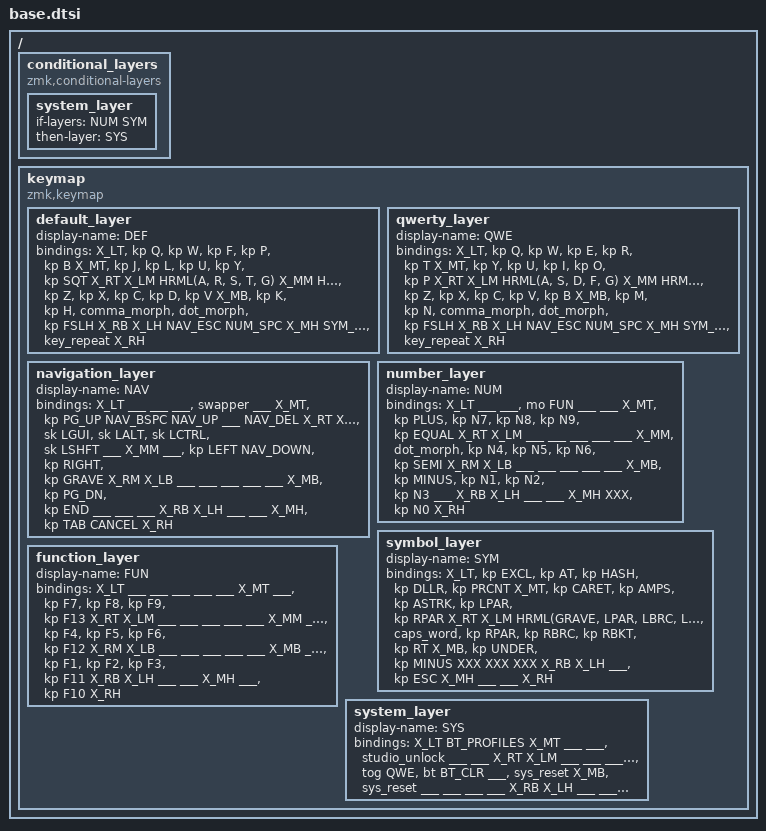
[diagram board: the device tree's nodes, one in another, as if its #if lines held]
// vim: set ts=4 sw=4 ft=devicetree foldmethod=marker foldmarker=[[[,]]]:

#include <behaviors.dtsi>
#include <dt-bindings/zmk/keys.h>
#include <dt-bindings/zmk/bt.h>

//[[[
/////////////////////////////////////////
// Layers
/////////////////////////////////////////
// Layers: Default, Qwerty, Navigation, Number, Symbol, System
#define DEF 0
#define QWE 1
#define NAV 2
#define NUM 3
#define SYM 4
#define FUN 5
#define SYS 6
/////////////////////////////////////////
//]]]



//[[[
/////////////////////////////////////////
// Variables
/////////////////////////////////////////
#define XXX &none
#define ___ &trans
#define KEYS_L LT0 LT1 LT2 LT3 LT4 LM0 LM1 LM2 LM3 LM4 LB0 LB1 LB2 LB3 LB4 // left hand
#define KEYS_R RT0 RT1 RT2 RT3 RT4 RM0 RM1 RM2 RM3 RM4 RB0 RB1 RB2 RB3 RB4 // right hand

#if defined LH2
  #define THUMBS LH2 LH1 LH0 RH0 RH1 RH2 // thumbs on 36 keys
#else
  #define THUMBS LH1 LH0 RH0 RH1 // thumbs on 34 keys
#endif

#ifdef CONFIG_WIRELESS
    #define BT_PROFILES &bt BT_SEL 0 &bt BT_SEL 1 &bt BT_SEL 2 &bt BT_SEL 3 &bt BT_SEL 4
#else
    #define BT_PROFILES ___ ___ ___ ___ ___
#endif
/////////////////////////////////////////
//]]]



//[[[
/////////////////////////////////////////
// Import functionalities
/////////////////////////////////////////
#include "fillers.dtsi"
#include "morph.dtsi"
#include "combos.dtsi"
#include "behaviors.dtsi"
/////////////////////////////////////////
//]]]



//[[[
/////////////////////////////////////////
// Aliases
/////////////////////////////////////////
//      Hyper       keys
#define LEFT_HYPER  LS(LC(LA(LGUI)))
#define LHYPER      LEFT_HYPER
#define LMEH        LS(LC(LALT))
#define RIGHT_HYPER RS(RC(RA(RGUI)))
#define RHYPER      RIGHT_HYPER
#define RMEH        RS(RC(RALT))
//      aliases
#define BTLOADER    &bootloader
#define CANCEL      &kp K_CANCEL
#define NAV_BSPC    &mt LC(BSPC) BSPC
#define NAV_DEL     &mt LC(DEL)  DEL
#define NAV_DOWN    &mt LC(END)  DOWN
#define NAV_UP      &mt LC(HOME) UP
#define STUDIO      &studio_unlock

//      layer       aliases
#define NAV_ESC     &escape_morph
#define NUM_SPC     &space_morph
#define SYM_ENT     &lt SYM ENTER

//      some        functions
#define LH(key)     LS(LC(LA(LG(key))))
#define LM(key)     LS(LC(LA(key)))
#define RH(key)     RS(RC(RA(RG(key))))
#define RM(key)     RS(RC(RA(key)))
/////////////////////////////////////////
//]]]



//[[[
/////////////////////////////////////////
// Home row mods macro
/////////////////////////////////////////
// GUI -> ALT -> CTRL -> SHFT  -> HYPER    |    HYPER -> SHFT -> CTRL -> ALT -> GUI
#define HRML(k1,k2,k3,k4,k5) &hml LGUI  k1 &hml LALT  k2 &hml LCTRL k3 &hml LSHFT k4 &hml LHYPER k5
#define HRMR(k1,k2,k3,k4,k5) &hmr RHYPER k1 &hmr RSHFT k2 &hmr RCTRL k3 &hmr RALT  k4 &hmr RGUI  k5
/////////////////////////////////////////
//]]]



//[[[
/////////////////////////////////////////
// Keymap config
/////////////////////////////////////////
/ {
    conditional_layers {
        compatible = "zmk,conditional-layers";
        system_layer {
            if-layers = <NUM SYM>;
            then-layer = <SYS>;
        };
    };

    keymap {
        compatible = "zmk,keymap";
        default_layer {
            display-name = "DEF";
            bindings = <
        //╭──────╮ ╭──────────┬──────────┬──────────┬──────────┬──────────╮ ╭──────╮ ╭──────────┬──────────┬──────────┬──────────┬──────────╮ ╭──────╮
            X_LT     &kp Q      &kp W      &kp F      &kp P      &kp B        X_MT     &kp J      &kp L      &kp U      &kp Y      &kp SQT      X_RT
        //├──────┤ ├──────────┼──────────┼──────────┼──────────┼──────────┤ ├──────┤ ├──────────┼──────────┼──────────┼──────────┼──────────┤ ├──────┤
            X_LM     HRML(A,        R,         S,         T,        G)        X_MM     HRMR(M,       N,        E,         I,          O)        X_RM
        //├──────┤ ├──────────┼──────────┼──────────┼──────────┼──────────┤ ├──────┤ ├──────────┼──────────┼──────────┼──────────┼──────────┤ ├──────┤
            X_LB     &kp Z      &kp X      &kp C      &kp D      &kp V        X_MB     &kp K      &kp H      &comma_morph  &dot_morph &kp FSLH  X_RB
        //├──────┤ ╰──────────┴──────────┴──────────┼──────────┼──────────┤ ├──────┤ ├──────────┼──────────┼──────────┴──────────┴──────────╯ ├──────┤
            X_LH                                      NAV_ESC    NUM_SPC      X_MH     SYM_ENT    &key_repeat                                   X_RH
        //╰──────╯                                  ╰──────────┴──────────╯ ╰──────╯ ╰──────────┴──────────╯                                  ╰──────╯
            >;
        };

        qwerty_layer {
            display-name = "QWE";
            bindings = <
        //╭──────╮ ╭──────────┬──────────┬──────────┬──────────┬──────────╮ ╭──────╮ ╭──────────┬──────────┬──────────┬──────────┬──────────╮ ╭──────╮
            X_LT     &kp Q      &kp W      &kp E      &kp R      &kp T        X_MT     &kp Y      &kp U      &kp I      &kp O      &kp P        X_RT
        //├──────┤ ├──────────┼──────────┼──────────┼──────────┼──────────┤ ├──────┤ ├──────────┼──────────┼──────────┼──────────┼──────────┤ ├──────┤
            X_LM     HRML(A,        S,         D,         F,        G)        X_MM     HRMR(H,         J,        K,         L,       SEMI)      X_RM
        //├──────┤ ├──────────┼──────────┼──────────┼──────────┼──────────┤ ├──────┤ ├──────────┼──────────┼──────────┼──────────┼──────────┤ ├──────┤
            X_LB     &kp Z      &kp X      &kp C      &kp V      &kp B        X_MB     &kp M      &kp N      &comma_morph  &dot_morph &kp FSLH  X_RB
        //├──────┤ ╰──────────┴──────────┴──────────┼──────────┼──────────┤ ├──────┤ ├──────────┼──────────┼──────────┴──────────┴──────────╯ ├──────┤
            X_LH                                      NAV_ESC    NUM_SPC      X_MH     SYM_ENT    &key_repeat                                   X_RH
        //╰──────╯                                  ╰──────────┴──────────╯ ╰──────╯ ╰──────────┴──────────╯                                  ╰──────╯
            >;
        };

        navigation_layer {
            display-name = "NAV";
            bindings = <
        //╭──────╮ ╭──────────┬──────────┬──────────┬──────────┬──────────╮ ╭──────╮ ╭──────────┬──────────┬──────────┬──────────┬──────────╮ ╭──────╮
            X_LT     ___        ___        ___        &swapper   ___          X_MT     &kp PG_UP  NAV_BSPC   NAV_UP     ___        NAV_DEL      X_RT
        //├──────┤ ├──────────┼──────────┼──────────┼──────────┼──────────┤ ├──────┤ ├──────────┼──────────┼──────────┼──────────┼──────────┤ ├──────┤
            X_LM     &sk LGUI   &sk LALT   &sk LCTRL  &sk LSHFT  ___          X_MM     ___        &kp LEFT   NAV_DOWN   &kp RIGHT  &kp GRAVE    X_RM
        //├──────┤ ├──────────┼──────────┼──────────┼──────────┼──────────┤ ├──────┤ ├──────────┼──────────┼──────────┼──────────┼──────────┤ ├──────┤
            X_LB     ___        ___        ___        ___        ___          X_MB     &kp PG_DN  &kp END    ___        ___        ___          X_RB
        //├──────┤ ╰──────────┴──────────┴──────────┼──────────┼──────────┤ ├──────┤ ├──────────┼──────────┼──────────┴──────────┴──────────╯ ├──────┤
            X_LH                                      ___        ___          X_MH     &kp TAB    CANCEL                                        X_RH
        //╰──────╯                                  ╰──────────┴──────────╯ ╰──────╯ ╰──────────┴──────────╯                                  ╰──────╯
            >;
        };

        number_layer {
            display-name = "NUM";
            bindings = <
        //╭──────╮ ╭──────────┬──────────┬──────────┬──────────┬──────────╮ ╭──────╮ ╭──────────┬──────────┬──────────┬──────────┬──────────╮ ╭──────╮
            X_LT     ___        ___        &mo FUN    ___        ___          X_MT     &kp PLUS   &kp N7     &kp N8     &kp N9     &kp EQUAL    X_RT
        //├──────┤ ├──────────┼──────────┼──────────┼──────────┼──────────┤ ├──────┤ ├──────────┼──────────┼──────────┼──────────┼──────────┤ ├──────┤
            X_LM     ___        ___        ___        ___        ___          X_MM     &dot_morph &kp N4     &kp N5     &kp N6     &kp SEMI     X_RM
        //├──────┤ ├──────────┼──────────┼──────────┼──────────┼──────────┤ ├──────┤ ├──────────┼──────────┼──────────┼──────────┼──────────┤ ├──────┤
            X_LB     ___        ___        ___        ___        ___          X_MB     &kp MINUS  &kp N1     &kp N2     &kp N3     ___          X_RB
        //├──────┤ ╰──────────┴──────────┴──────────┼──────────┼──────────┤ ├──────┤ ├──────────┼──────────┼──────────┴──────────┴──────────╯ ├──────┤
            X_LH                                      ___        ___          X_MH     XXX        &kp N0                                        X_RH
        //╰──────╯                                  ╰──────────┴──────────╯ ╰──────╯ ╰──────────┴──────────╯                                  ╰──────╯
            >;
        };

        symbol_layer {
            display-name = "SYM";
            bindings = <
        //╭──────╮ ╭──────────┬──────────┬──────────┬──────────┬──────────╮ ╭──────╮ ╭──────────┬──────────┬──────────┬──────────┬──────────╮ ╭──────╮
            X_LT     &kp EXCL   &kp AT     &kp HASH   &kp DLLR   &kp PRCNT    X_MT     &kp CARET  &kp AMPS   &kp ASTRK  &kp LPAR   &kp RPAR     X_RT
        //├──────┤ ├──────────┼──────────┼──────────┼──────────┼──────────┤ ├──────┤ ├──────────┼──────────┼──────────┼──────────┼──────────┤ ├──────┤
            X_LM     HRML(GRAVE,  LPAR,     LBRC,       LBKT,       LT)       X_MM     HRMR(GT,     RBKT,     RBRC,       RPAR,     TILDE)      X_RM
        //├──────┤ ├──────────┼──────────┼──────────┼──────────┼──────────┤ ├──────┤ ├──────────┼──────────┼──────────┼──────────┼──────────┤ ├──────┤
            X_LB    &caps_word  &kp RPAR   &kp RBRC   &kp RBKT   &kp RT       X_MB     &kp UNDER  &kp MINUS  XXX        XXX        XXX          X_RB
        //├──────┤ ╰──────────┴──────────┴──────────┼──────────┼──────────┤ ├──────┤ ├──────────┼──────────┼──────────┴──────────┴──────────╯ ├──────┤
            X_LH                                      ___        &kp ESC      X_MH     ___        ___                                           X_RH
        //╰──────╯                                  ╰──────────┴──────────╯ ╰──────╯ ╰──────────┴──────────╯                                  ╰──────╯
            >;
        };

        function_layer {
            display-name = "FUN";
            bindings = <
        //╭──────╮ ╭──────────┬──────────┬──────────┬──────────┬──────────╮ ╭──────╮ ╭──────────┬──────────┬──────────┬──────────┬──────────╮ ╭──────╮
            X_LT     ___        ___        ___        ___        ___          X_MT     ___        &kp F7     &kp F8     &kp F9     &kp F13      X_RT
        //├──────┤ ├──────────┼──────────┼──────────┼──────────┼──────────┤ ├──────┤ ├──────────┼──────────┼──────────┼──────────┼──────────┤ ├──────┤
            X_LM     ___        ___        ___        ___        ___          X_MM     ___        &kp F4     &kp F5     &kp F6     &kp F12      X_RM
        //├──────┤ ├──────────┼──────────┼──────────┼──────────┼──────────┤ ├──────┤ ├──────────┼──────────┼──────────┼──────────┼──────────┤ ├──────┤
            X_LB     ___        ___        ___        ___        ___          X_MB     ___        &kp F1     &kp F2     &kp F3     &kp F11      X_RB
        //├──────┤ ╰──────────┴──────────┴──────────┼──────────┼──────────┤ ├──────┤ ├──────────┼──────────┼──────────┴──────────┴──────────╯ ├──────┤
            X_LH                                      ___        ___          X_MH     ___        &kp F10                                       X_RH
        //╰──────╯                                  ╰──────────┴──────────╯ ╰──────╯ ╰──────────┴──────────╯                                  ╰──────╯
            >;
        };

        system_layer {
            display-name = "SYS";
            bindings = <
        //╭──────╮ ╭──────────┬──────────┬──────────┬──────────┬──────────╮ ╭──────╮ ╭──────────┬──────────┬──────────┬──────────┬──────────╮ ╭──────╮
            X_LT                           BT_PROFILES                        X_MT     ___        ___        &studio_unlock ___        ___      X_RT
        //├──────┤ ├──────────┼──────────┼──────────┼──────────┼──────────┤ ├──────┤ ├──────────┼──────────┼──────────┼──────────┼──────────┤ ├──────┤
            X_LM     ___        ___         ___        ___       BTLOADER     X_MM     BTLOADER   ___        ___        ___        ___          X_RM
        //├──────┤ ├──────────┼──────────┼──────────┼──────────┼──────────┤ ├──────┤ ├──────────┼──────────┼──────────┼──────────┼──────────┤ ├──────┤
            X_LB     ___        &tog QWE   &bt BT_CLR  ___       &sys_reset   X_MB     &sys_reset ___        ___        ___        ___          X_RB
        //├──────┤ ╰──────────┴──────────┴──────────┼──────────┼──────────┤ ├──────┤ ├──────────┼──────────┼──────────┴──────────┴──────────╯ ├──────┤
            X_LH                                       ___       ___          X_MH     ___        ___                                           X_RH
        //╰──────╯                                  ╰──────────┴──────────╯ ╰──────╯ ╰──────────┴──────────╯                                  ╰──────╯
            >;
        };
    };
};
/////////////////////////////////////////



//[[[
/////////////////////////////////////////
// Encoder related config
/////////////////////////////////////////
#ifdef CONFIG_ENCODER
  #include "encoder.dtsi"
#endif
/////////////////////////////////////////
